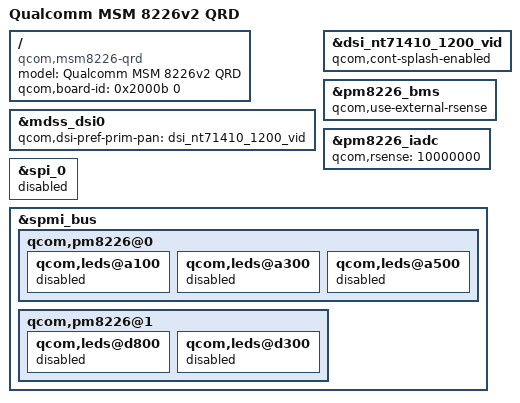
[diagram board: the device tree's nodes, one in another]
/* Copyright (c) 2013, The Linux Foundation. All rights reserved.
 *
 * This program is free software; you can redistribute it and/or modify
 * it under the terms of the GNU General Public License version 2 and
 * only version 2 as published by the Free Software Foundation.
 *
 * This program is distributed in the hope that it will be useful,
 * but WITHOUT ANY WARRANTY; without even the implied warranty of
 * MERCHANTABILITY or FITNESS FOR A PARTICULAR PURPOSE.  See the
 * GNU General Public License for more details.
 */

/dts-v1/;
/include/ "msm8226-v2.dtsi"
/include/ "msm8226-qrd.dtsi"
/ {
	model = "Qualcomm MSM 8226v2 QRD";
	compatible = "qcom,msm8226-qrd", "qcom,msm8226", "qcom,qrd";
	qcom,board-id = <0x2000b 0>;
};

&mdss_dsi0 {
	qcom,dsi-pref-prim-pan = <&dsi_nt71410_1200_vid>;
};

&dsi_nt71410_1200_vid{
	qcom,cont-splash-enabled;
};

&pm8226_bms {
        qcom,use-external-rsense;
};

&pm8226_iadc {
	qcom,rsense = <10000000>;
};

&spi_0 {
        status = "disabled";
};


&spmi_bus {
	qcom,pm8226@0 {
		qcom,leds@a100 {
                        status = "disabled";
		};
		qcom,leds@a300 {
                        status = "disabled";
		};
		qcom,leds@a500 {
                        status = "disbled";
		};
	};
        qcom,pm8226@1 {
                qcom,leds@d800 {
                        status = "disabled";
                };
		qcom,leds@d300 {
			status = "disabled";
		};
        };
};
